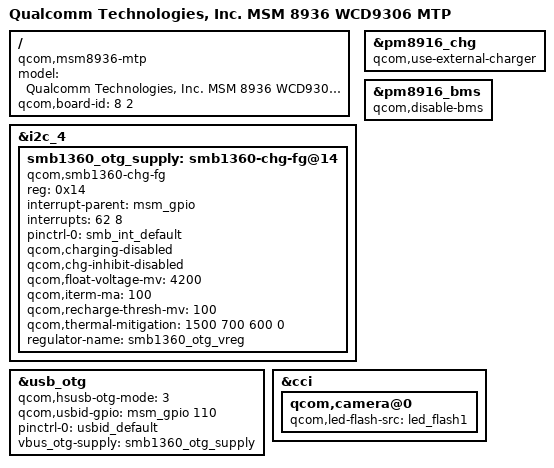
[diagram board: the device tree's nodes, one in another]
/* Copyright (c) 2014, The Linux Foundation. All rights reserved.
*
* This program is free software; you can redistribute it and/or modify
* it under the terms of the GNU General Public License version 2 and
* only version 2 as published by the Free Software Foundation.
*
* This program is distributed in the hope that it will be useful,
* but WITHOUT ANY WARRANTY; without even the implied warranty of
* MERCHANTABILITY or FITNESS FOR A PARTICULAR PURPOSE.  See the
* GNU General Public License for more details.
*/

/dts-v1/;

#include "msm8936.dtsi"
#include "msm8939-mtp.dtsi"
#include "msm8939-audio-external_codec.dtsi"

/ {
	model = "Qualcomm Technologies, Inc. MSM 8936 WCD9306 MTP";
	compatible = "qcom,msm8936-mtp", "qcom,msm8936", "qcom,mtp";
	qcom,board-id = <8 2>;
};

&i2c_4 {
	smb1360_otg_supply: smb1360-chg-fg@14 {
		compatible = "qcom,smb1360-chg-fg";
		reg = <0x14>;
		interrupt-parent = <&msm_gpio>;
		interrupts = <62 8>;
		pinctrl-names = "default";
		pinctrl-0 = <&smb_int_default>;
		qcom,charging-disabled;
		qcom,chg-inhibit-disabled;
		qcom,float-voltage-mv = <4200>;
		qcom,iterm-ma = <100>;
		qcom,recharge-thresh-mv = <100>;
		qcom,thermal-mitigation = <1500 700 600 0>;
		regulator-name = "smb1360_otg_vreg";
	};
};

&pm8916_chg {
	status = "ok";
	qcom,use-external-charger;
};

&pm8916_bms {
	status = "ok";
	qcom,disable-bms;
};

&usb_otg {
	qcom,hsusb-otg-mode = <3>;
	qcom,usbid-gpio = <&msm_gpio 110 0>;
	pinctrl-names = "default";
	pinctrl-0 = <&usbid_default>;
	vbus_otg-supply = <&smb1360_otg_supply>;
};

&cci {
	qcom,camera@0 {
		qcom,led-flash-src = <&led_flash1>;
	};
};
